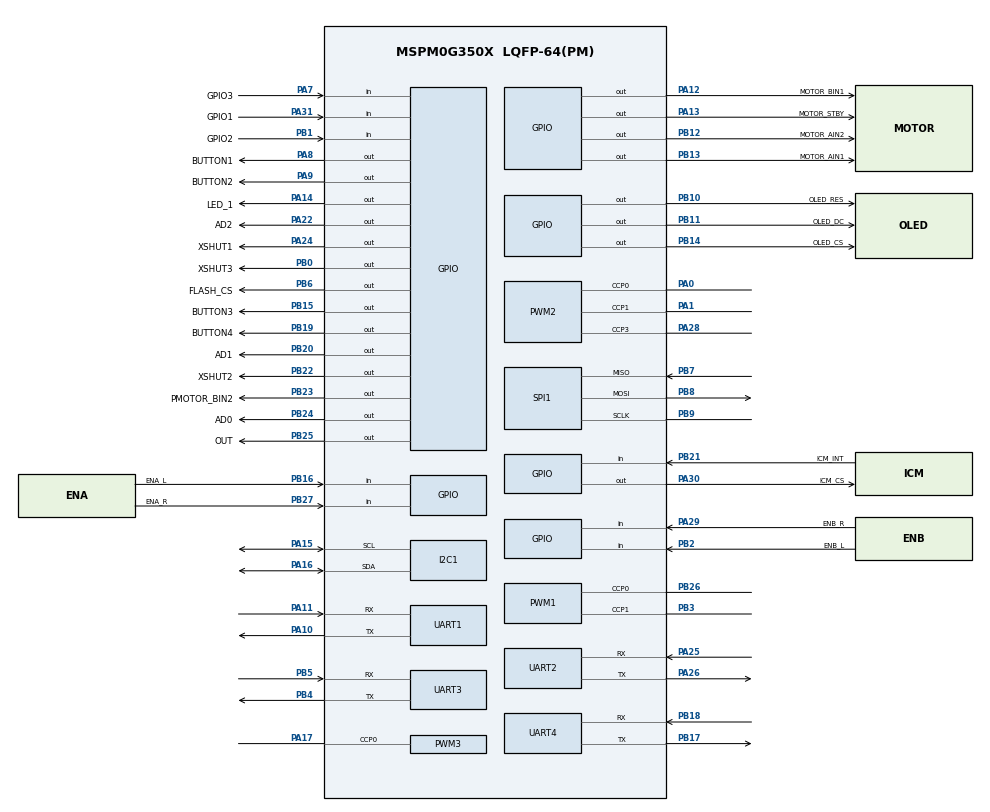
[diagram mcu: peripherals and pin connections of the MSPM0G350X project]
/**
 * @cliArgs --device "MSPM0G350X" --part "Default" --package "LQFP-64(PM)" --product "mspm0_sdk@2.10.00.04"
 * @versions {"tool":"1.26.2+4477"}
 */

/**
 * Import the modules used in this configuration.
 */
const ADC12   = scripting.addModule("/ti/driverlib/ADC12", {}, false);
const ADC121  = ADC12.addInstance();
const GPIO    = scripting.addModule("/ti/driverlib/GPIO", {}, false);
const GPIO1   = GPIO.addInstance();
const GPIO2   = GPIO.addInstance();
const GPIO3   = GPIO.addInstance();
const GPIO4   = GPIO.addInstance();
const GPIO5   = GPIO.addInstance();
const GPIO6   = GPIO.addInstance();
const GPIO7   = GPIO.addInstance();
const GPIO8   = GPIO.addInstance();
const GPIO9   = GPIO.addInstance();
const I2C     = scripting.addModule("/ti/driverlib/I2C", {}, false);
const I2C1    = I2C.addInstance();
const PWM     = scripting.addModule("/ti/driverlib/PWM", {}, false);
const PWM1    = PWM.addInstance();
const PWM2    = PWM.addInstance();
const PWM3    = PWM.addInstance();
const SPI     = scripting.addModule("/ti/driverlib/SPI", {}, false);
const SPI1    = SPI.addInstance();
const SYSCTL  = scripting.addModule("/ti/driverlib/SYSCTL");
const SYSTICK = scripting.addModule("/ti/driverlib/SYSTICK");
const TIMER   = scripting.addModule("/ti/driverlib/TIMER", {}, false);
const TIMER1  = TIMER.addInstance();
const TIMER2  = TIMER.addInstance();
const UART    = scripting.addModule("/ti/driverlib/UART", {}, false);
const UART1   = UART.addInstance();
const UART2   = UART.addInstance();
const UART3   = UART.addInstance();
const UART4   = UART.addInstance();

/**
 * Write custom configuration values to the imported modules.
 */
const divider6       = system.clockTree["PLL_CLK2X_DIV"];
divider6.divideValue = 4;

const divider9       = system.clockTree["UDIV"];
divider9.divideValue = 2;

const multiplier2         = system.clockTree["PLL_QDIV"];
multiplier2.multiplyValue = 5;

const mux4       = system.clockTree["EXHFMUX"];
mux4.inputSelect = "EXHFMUX_XTAL";

const mux8       = system.clockTree["HSCLKMUX"];
mux8.inputSelect = "HSCLKMUX_SYSPLL2X";

ADC121.$name                             = "BAT_ADC";
ADC121.sampClkSrc                        = "DL_ADC12_CLOCK_ULPCLK";
ADC121.sampleTime0                       = "200us";
ADC121.enabledInterrupts                 = ["DL_ADC12_INTERRUPT_MEM0_RESULT_LOADED"];
ADC121.powerDownMode                     = "DL_ADC12_POWER_DOWN_MODE_MANUAL";
ADC121.adcMem0avgen                      = true;
ADC121.hwNumerator                       = "DL_ADC12_HW_AVG_NUM_ACC_8";
ADC121.peripheral.$assign                = "ADC0";
ADC121.peripheral.adcPin0.$assign        = "PA27";
ADC121.adcPin0Config.hideOutputInversion = scripting.forceWrite(false);
ADC121.adcPin0Config.$name               = "ti_driverlib_gpio_GPIOPinGeneric8";

const Board = scripting.addModule("/ti/driverlib/Board", {}, false);

GPIO1.$name                          = "OLED";
GPIO1.associatedPins.create(3);
GPIO1.associatedPins[0].$name        = "OLED_CS";
GPIO1.associatedPins[0].assignedPort = "PORTB";
GPIO1.associatedPins[0].assignedPin  = "14";
GPIO1.associatedPins[0].initialValue = "SET";
GPIO1.associatedPins[0].pin.$assign  = "PB14";
GPIO1.associatedPins[1].$name        = "OLED_DC";
GPIO1.associatedPins[1].assignedPort = "PORTB";
GPIO1.associatedPins[1].assignedPin  = "11";
GPIO1.associatedPins[1].pin.$assign  = "PB11";
GPIO1.associatedPins[2].$name        = "OLED_RES";
GPIO1.associatedPins[2].assignedPort = "PORTB";
GPIO1.associatedPins[2].assignedPin  = "10";
GPIO1.associatedPins[2].pin.$assign  = "PB10";

GPIO2.$name                          = "FLASH";
GPIO2.associatedPins[0].$name        = "FLASH_CS";
GPIO2.associatedPins[0].assignedPort = "PORTB";
GPIO2.associatedPins[0].assignedPin  = "6";
GPIO2.associatedPins[0].initialValue = "SET";
GPIO2.associatedPins[0].pin.$assign  = "PB6";

GPIO3.$name                              = "ICM";
GPIO3.associatedPins.create(2);
GPIO3.associatedPins[0].$name            = "ICM_CS";
GPIO3.associatedPins[0].initialValue     = "SET";
GPIO3.associatedPins[0].internalResistor = "PULL_UP";
GPIO3.associatedPins[0].assignedPort     = "PORTA";
GPIO3.associatedPins[0].assignedPin      = "30";
GPIO3.associatedPins[0].pin.$assign      = "PA30";
GPIO3.associatedPins[1].$name            = "ICM_INT";
GPIO3.associatedPins[1].assignedPort     = "PORTB";
GPIO3.associatedPins[1].assignedPin      = "21";
GPIO3.associatedPins[1].direction        = "INPUT";
GPIO3.associatedPins[1].internalResistor = "PULL_UP";
GPIO3.associatedPins[1].pin.$assign      = "PB21";

GPIO4.$name                          = "MOTOR";
GPIO4.associatedPins.create(5);
GPIO4.associatedPins[0].$name        = "MOTOR_AIN2";
GPIO4.associatedPins[0].assignedPort = "PORTB";
GPIO4.associatedPins[0].assignedPin  = "12";
GPIO4.associatedPins[0].initialValue = "SET";
GPIO4.associatedPins[0].pin.$assign  = "PB12";
GPIO4.associatedPins[1].$name        = "MOTOR_AIN1";
GPIO4.associatedPins[1].assignedPort = "PORTB";
GPIO4.associatedPins[1].assignedPin  = "13";
GPIO4.associatedPins[1].initialValue = "SET";
GPIO4.associatedPins[1].pin.$assign  = "PB13";
GPIO4.associatedPins[2].$name        = "MOTOR_STBY";
GPIO4.associatedPins[2].assignedPort = "PORTA";
GPIO4.associatedPins[2].assignedPin  = "13";
GPIO4.associatedPins[2].pin.$assign  = "PA13";
GPIO4.associatedPins[3].$name        = "MOTOR_BIN1";
GPIO4.associatedPins[3].assignedPort = "PORTA";
GPIO4.associatedPins[3].assignedPin  = "12";
GPIO4.associatedPins[3].initialValue = "SET";
GPIO4.associatedPins[3].pin.$assign  = "PA12";
GPIO4.associatedPins[4].$name        = "PMOTOR_BIN2";
GPIO4.associatedPins[4].assignedPort = "PORTB";
GPIO4.associatedPins[4].assignedPin  = "23";
GPIO4.associatedPins[4].initialValue = "SET";
GPIO4.associatedPins[4].pin.$assign  = "PB23";

GPIO5.$name                               = "ENCODER";
GPIO5.associatedPins.create(4);
GPIO5.associatedPins[0].$name             = "ENA_L";
GPIO5.associatedPins[0].assignedPort      = "PORTB";
GPIO5.associatedPins[0].assignedPin       = "16";
GPIO5.associatedPins[0].direction         = "INPUT";
GPIO5.associatedPins[0].interruptEn       = true;
GPIO5.associatedPins[0].polarity          = "RISE_FALL";
GPIO5.associatedPins[0].interruptPriority = "1";
GPIO5.associatedPins[0].inputFilter       = "8_CYCLES";
GPIO5.associatedPins[0].internalResistor  = "PULL_UP";
GPIO5.associatedPins[0].pin.$assign       = "PB16";
GPIO5.associatedPins[1].$name             = "ENB_L";
GPIO5.associatedPins[1].assignedPort      = "PORTB";
GPIO5.associatedPins[1].assignedPin       = "2";
GPIO5.associatedPins[1].direction         = "INPUT";
GPIO5.associatedPins[1].interruptEn       = true;
GPIO5.associatedPins[1].polarity          = "RISE_FALL";
GPIO5.associatedPins[1].interruptPriority = "1";
GPIO5.associatedPins[1].inputFilter       = "8_CYCLES";
GPIO5.associatedPins[1].internalResistor  = "PULL_UP";
GPIO5.associatedPins[1].pin.$assign       = "PB2";
GPIO5.associatedPins[2].$name             = "ENA_R";
GPIO5.associatedPins[2].assignedPin       = "27";
GPIO5.associatedPins[2].assignedPort      = "PORTB";
GPIO5.associatedPins[2].direction         = "INPUT";
GPIO5.associatedPins[2].interruptEn       = true;
GPIO5.associatedPins[2].polarity          = "RISE_FALL";
GPIO5.associatedPins[2].interruptPriority = "1";
GPIO5.associatedPins[2].inputFilter       = "8_CYCLES";
GPIO5.associatedPins[2].internalResistor  = "PULL_UP";
GPIO5.associatedPins[2].pin.$assign       = "PB27";
GPIO5.associatedPins[3].$name             = "ENB_R";
GPIO5.associatedPins[3].assignedPort      = "PORTA";
GPIO5.associatedPins[3].assignedPin       = "29";
GPIO5.associatedPins[3].direction         = "INPUT";
GPIO5.associatedPins[3].polarity          = "RISE_FALL";
GPIO5.associatedPins[3].interruptEn       = true;
GPIO5.associatedPins[3].interruptPriority = "1";
GPIO5.associatedPins[3].inputFilter       = "8_CYCLES";
GPIO5.associatedPins[3].internalResistor  = "PULL_UP";
GPIO5.associatedPins[3].pin.$assign       = "PA29";

GPIO6.$name                          = "GRAYSCALE";
GPIO6.associatedPins.create(4);
GPIO6.associatedPins[0].$name        = "OUT";
GPIO6.associatedPins[0].assignedPort = "PORTB";
GPIO6.associatedPins[0].assignedPin  = "25";
GPIO6.associatedPins[0].pin.$assign  = "PB25";
GPIO6.associatedPins[1].$name        = "AD0";
GPIO6.associatedPins[1].assignedPort = "PORTB";
GPIO6.associatedPins[1].assignedPin  = "24";
GPIO6.associatedPins[1].pin.$assign  = "PB24";
GPIO6.associatedPins[2].$name        = "AD1";
GPIO6.associatedPins[2].assignedPort = "PORTB";
GPIO6.associatedPins[2].assignedPin  = "20";
GPIO6.associatedPins[2].pin.$assign  = "PB20";
GPIO6.associatedPins[3].$name        = "AD2";
GPIO6.associatedPins[3].assignedPort = "PORTA";
GPIO6.associatedPins[3].assignedPin  = "22";
GPIO6.associatedPins[3].pin.$assign  = "PA22";

GPIO7.$name                               = "LASER";
GPIO7.associatedPins.create(6);
GPIO7.associatedPins[0].$name             = "XSHUT1";
GPIO7.associatedPins[0].assignedPort      = "PORTA";
GPIO7.associatedPins[0].assignedPin       = "24";
GPIO7.associatedPins[0].initialValue      = "SET";
GPIO7.associatedPins[0].pin.$assign       = "PA24";
GPIO7.associatedPins[1].$name             = "GPIO1";
GPIO7.associatedPins[1].assignedPort      = "PORTA";
GPIO7.associatedPins[1].assignedPin       = "31";
GPIO7.associatedPins[1].direction         = "INPUT";
GPIO7.associatedPins[1].interruptEn       = true;
GPIO7.associatedPins[1].polarity          = "FALL";
GPIO7.associatedPins[1].interruptPriority = "3";
GPIO7.associatedPins[1].internalResistor  = "PULL_UP";
GPIO7.associatedPins[1].pin.$assign       = "PA31";
GPIO7.associatedPins[2].$name             = "XSHUT2";
GPIO7.associatedPins[2].assignedPort      = "PORTB";
GPIO7.associatedPins[2].assignedPin       = "22";
GPIO7.associatedPins[2].initialValue      = "SET";
GPIO7.associatedPins[2].pin.$assign       = "PB22";
GPIO7.associatedPins[3].$name             = "GPIO2";
GPIO7.associatedPins[3].assignedPort      = "PORTB";
GPIO7.associatedPins[3].assignedPin       = "1";
GPIO7.associatedPins[3].direction         = "INPUT";
GPIO7.associatedPins[3].polarity          = "FALL";
GPIO7.associatedPins[3].interruptEn       = true;
GPIO7.associatedPins[3].interruptPriority = "3";
GPIO7.associatedPins[3].internalResistor  = "PULL_UP";
GPIO7.associatedPins[3].pin.$assign       = "PB1";
GPIO7.associatedPins[4].$name             = "XSHUT3";
GPIO7.associatedPins[4].assignedPort      = "PORTB";
GPIO7.associatedPins[4].assignedPin       = "0";
GPIO7.associatedPins[4].initialValue      = "SET";
GPIO7.associatedPins[4].pin.$assign       = "PB0";
GPIO7.associatedPins[5].$name             = "GPIO3";
GPIO7.associatedPins[5].assignedPort      = "PORTA";
GPIO7.associatedPins[5].assignedPin       = "7";
GPIO7.associatedPins[5].direction         = "INPUT";
GPIO7.associatedPins[5].interruptEn       = true;
GPIO7.associatedPins[5].polarity          = "FALL";
GPIO7.associatedPins[5].interruptPriority = "3";
GPIO7.associatedPins[5].internalResistor  = "PULL_UP";
GPIO7.associatedPins[5].pin.$assign       = "PA7";

GPIO8.$name                          = "BUTTON";
GPIO8.associatedPins.create(4);
GPIO8.associatedPins[0].$name        = "BUTTON1";
GPIO8.associatedPins[0].assignedPort = "PORTA";
GPIO8.associatedPins[0].assignedPin  = "8";
GPIO8.associatedPins[0].pin.$assign  = "PA8";
GPIO8.associatedPins[1].$name        = "BUTTON2";
GPIO8.associatedPins[1].assignedPort = "PORTA";
GPIO8.associatedPins[1].assignedPin  = "9";
GPIO8.associatedPins[1].pin.$assign  = "PA9";
GPIO8.associatedPins[2].$name        = "BUTTON3";
GPIO8.associatedPins[2].assignedPort = "PORTB";
GPIO8.associatedPins[2].assignedPin  = "15";
GPIO8.associatedPins[2].pin.$assign  = "PB15";
GPIO8.associatedPins[3].$name        = "BUTTON4";
GPIO8.associatedPins[3].assignedPort = "PORTB";
GPIO8.associatedPins[3].assignedPin  = "19";
GPIO8.associatedPins[3].pin.$assign  = "PB19";

GPIO9.$name                          = "LED";
GPIO9.associatedPins[0].$name        = "LED_1";
GPIO9.associatedPins[0].assignedPort = "PORTA";
GPIO9.associatedPins[0].assignedPin  = "14";
GPIO9.associatedPins[0].initialValue = "SET";
GPIO9.associatedPins[0].pin.$assign  = "PA14";

I2C1.$name                           = "I2C_0";
I2C1.basicEnableController           = true;
I2C1.basicControllerStandardBusSpeed = "FastPlus";
I2C1.peripheral.$assign              = "I2C1";
I2C1.peripheral.sdaPin.$assign       = "PA16";
I2C1.peripheral.sclPin.$assign       = "PA15";
I2C1.sdaPinConfig.$name              = "ti_driverlib_gpio_GPIOPinGeneric9";
I2C1.sclPinConfig.$name              = "ti_driverlib_gpio_GPIOPinGeneric15";

PWM1.$name                              = "PWM_Motor";
PWM1.pwmMode                            = "EDGE_ALIGN_UP";
PWM1.timerStartTimer                    = true;
PWM1.clockDivider                       = 4;
PWM1.peripheral.$assign                 = "TIMG6";
PWM1.peripheral.ccp0Pin.$assign         = "PB26";
PWM1.peripheral.ccp1Pin.$assign         = "PB3";
PWM1.PWM_CHANNEL_0.$name                = "ti_driverlib_pwm_PWMTimerCC0";
PWM1.PWM_CHANNEL_1.$name                = "ti_driverlib_pwm_PWMTimerCC2";
PWM1.ccp0PinConfig.direction            = scripting.forceWrite("OUTPUT");
PWM1.ccp0PinConfig.hideOutputInversion  = scripting.forceWrite(false);
PWM1.ccp0PinConfig.onlyInternalResistor = scripting.forceWrite(false);
PWM1.ccp0PinConfig.passedPeripheralType = scripting.forceWrite("Digital");
PWM1.ccp0PinConfig.$name                = "ti_driverlib_gpio_GPIOPinGeneric11";
PWM1.ccp1PinConfig.direction            = scripting.forceWrite("OUTPUT");
PWM1.ccp1PinConfig.hideOutputInversion  = scripting.forceWrite(false);
PWM1.ccp1PinConfig.onlyInternalResistor = scripting.forceWrite(false);
PWM1.ccp1PinConfig.passedPeripheralType = scripting.forceWrite("Digital");
PWM1.ccp1PinConfig.$name                = "ti_driverlib_gpio_GPIOPinGeneric10";

PWM2.$name                              = "PWM_SERVO";
PWM2.ccIndex                            = [0,1,3];
PWM2.PWM_CHANNEL_0.$name                = "ti_driverlib_pwm_PWMTimerCC1";
PWM2.PWM_CHANNEL_1.$name                = "ti_driverlib_pwm_PWMTimerCC3";
PWM2.ccp0PinConfig.direction            = scripting.forceWrite("OUTPUT");
PWM2.ccp0PinConfig.hideOutputInversion  = scripting.forceWrite(false);
PWM2.ccp0PinConfig.onlyInternalResistor = scripting.forceWrite(false);
PWM2.ccp0PinConfig.passedPeripheralType = scripting.forceWrite("Digital");
PWM2.ccp0PinConfig.$name                = "ti_driverlib_gpio_GPIOPinGeneric12";
PWM2.ccp1PinConfig.direction            = scripting.forceWrite("OUTPUT");
PWM2.ccp1PinConfig.hideOutputInversion  = scripting.forceWrite(false);
PWM2.ccp1PinConfig.onlyInternalResistor = scripting.forceWrite(false);
PWM2.ccp1PinConfig.passedPeripheralType = scripting.forceWrite("Digital");
PWM2.ccp1PinConfig.$name                = "ti_driverlib_gpio_GPIOPinGeneric13";
PWM2.peripheral.$assign                 = "TIMA0";
PWM2.peripheral.ccp0Pin.$assign         = "PA0";
PWM2.peripheral.ccp1Pin.$assign         = "PA1";
PWM2.peripheral.ccp3Pin.$assign         = "PA28";
PWM2.PWM_CHANNEL_3.$name                = "ti_driverlib_pwm_PWMTimerCC4";
PWM2.ccp3PinConfig.$name                = "ti_driverlib_gpio_GPIOPinGeneric14";

PWM3.$name                              = "PWM_BUZZER";
PWM3.ccIndex                            = [0];
PWM3.PWM_CHANNEL_0.$name                = "ti_driverlib_pwm_PWMTimerCC5";
PWM3.ccp0PinConfig.direction            = scripting.forceWrite("OUTPUT");
PWM3.ccp0PinConfig.hideOutputInversion  = scripting.forceWrite(false);
PWM3.ccp0PinConfig.onlyInternalResistor = scripting.forceWrite(false);
PWM3.ccp0PinConfig.passedPeripheralType = scripting.forceWrite("Digital");
PWM3.ccp0PinConfig.$name                = "ti_driverlib_gpio_GPIOPinGeneric5";
PWM3.peripheral.$assign                 = "TIMA1";
PWM3.peripheral.ccp0Pin.$assign         = "PA17";

SPI1.frameFormat                        = "MOTO3";
SPI1.$name                              = "SPI_1";
SPI1.targetBitRate                      = 20000000;
SPI1.sclkPinConfig.direction            = scripting.forceWrite("OUTPUT");
SPI1.sclkPinConfig.onlyInternalResistor = scripting.forceWrite(false);
SPI1.sclkPinConfig.passedPeripheralType = scripting.forceWrite("Digital");
SPI1.sclkPinConfig.$name                = "ti_driverlib_gpio_GPIOPinGeneric0";
SPI1.mosiPinConfig.direction            = scripting.forceWrite("OUTPUT");
SPI1.mosiPinConfig.hideOutputInversion  = scripting.forceWrite(false);
SPI1.mosiPinConfig.onlyInternalResistor = scripting.forceWrite(false);
SPI1.mosiPinConfig.passedPeripheralType = scripting.forceWrite("Digital");
SPI1.mosiPinConfig.$name                = "ti_driverlib_gpio_GPIOPinGeneric1";
SPI1.misoPinConfig.onlyInternalResistor = scripting.forceWrite(false);
SPI1.misoPinConfig.passedPeripheralType = scripting.forceWrite("Digital");
SPI1.misoPinConfig.$name                = "ti_driverlib_gpio_GPIOPinGeneric2";
SPI1.misoPinConfig.enableConfig         = true;
SPI1.peripheral.$assign                 = "SPI1";
SPI1.peripheral.sclkPin.$assign         = "PB9";
SPI1.peripheral.mosiPin.$assign         = "PB8";
SPI1.peripheral.misoPin.$assign         = "PB7";

SYSCTL.forceDefaultClkConfig = true;
SYSCTL.clockTreeEn           = true;

SYSTICK.periodEnable      = true;
SYSTICK.interruptEnable   = true;
SYSTICK.interruptPriority = "0";
SYSTICK.systickEnable     = true;
SYSTICK.period            = 80000;

TIMER1.interrupts  = ["ZERO"];
TIMER1.$name       = "TIMER_10ms";
TIMER1.timerPeriod = "10ms";
TIMER1.timerClkDiv = 8;
TIMER1.timerMode   = "PERIODIC";

TIMER2.$name              = "TIMER_2ms";
TIMER2.timerMode          = "PERIODIC";
TIMER2.interrupts         = ["ZERO"];
TIMER2.timerClkDiv        = 4;
TIMER2.interruptPriority  = "1";
TIMER2.timerPeriod        = "2ms";
TIMER2.peripheral.$assign = "TIMG7";

UART1.$name                            = "UART";
UART1.targetBaudRate                   = 115200;
UART1.enabledInterrupts                = ["RX"];
UART1.peripheral.$assign               = "UART0";
UART1.peripheral.rxPin.$assign         = "PA11";
UART1.peripheral.txPin.$assign         = "PA10";
UART1.txPinConfig.direction            = scripting.forceWrite("OUTPUT");
UART1.txPinConfig.hideOutputInversion  = scripting.forceWrite(false);
UART1.txPinConfig.onlyInternalResistor = scripting.forceWrite(false);
UART1.txPinConfig.passedPeripheralType = scripting.forceWrite("Digital");
UART1.txPinConfig.$name                = "ti_driverlib_gpio_GPIOPinGeneric6";
UART1.rxPinConfig.hideOutputInversion  = scripting.forceWrite(false);
UART1.rxPinConfig.onlyInternalResistor = scripting.forceWrite(false);
UART1.rxPinConfig.passedPeripheralType = scripting.forceWrite("Digital");
UART1.rxPinConfig.$name                = "ti_driverlib_gpio_GPIOPinGeneric7";
UART1.rxPinConfig.enableConfig         = true;
UART1.rxPinConfig.internalResistor     = "PULL_UP";

UART2.$name                            = "UART_3";
UART2.peripheral.$assign               = "UART3";
UART2.peripheral.rxPin.$assign         = "PA25";
UART2.peripheral.txPin.$assign         = "PA26";
UART2.txPinConfig.direction            = scripting.forceWrite("OUTPUT");
UART2.txPinConfig.hideOutputInversion  = scripting.forceWrite(false);
UART2.txPinConfig.onlyInternalResistor = scripting.forceWrite(false);
UART2.txPinConfig.passedPeripheralType = scripting.forceWrite("Digital");
UART2.txPinConfig.$name                = "ti_driverlib_gpio_GPIOPinGeneric16";
UART2.rxPinConfig.hideOutputInversion  = scripting.forceWrite(false);
UART2.rxPinConfig.onlyInternalResistor = scripting.forceWrite(false);
UART2.rxPinConfig.passedPeripheralType = scripting.forceWrite("Digital");
UART2.rxPinConfig.$name                = "ti_driverlib_gpio_GPIOPinGeneric17";

UART3.$name                            = "UART_WIRELESS";
UART3.peripheral.$assign               = "UART1";
UART3.peripheral.rxPin.$assign         = "PB5";
UART3.peripheral.txPin.$assign         = "PB4";
UART3.txPinConfig.direction            = scripting.forceWrite("OUTPUT");
UART3.txPinConfig.hideOutputInversion  = scripting.forceWrite(false);
UART3.txPinConfig.onlyInternalResistor = scripting.forceWrite(false);
UART3.txPinConfig.passedPeripheralType = scripting.forceWrite("Digital");
UART3.txPinConfig.$name                = "ti_driverlib_gpio_GPIOPinGeneric18";
UART3.rxPinConfig.hideOutputInversion  = scripting.forceWrite(false);
UART3.rxPinConfig.onlyInternalResistor = scripting.forceWrite(false);
UART3.rxPinConfig.passedPeripheralType = scripting.forceWrite("Digital");
UART3.rxPinConfig.$name                = "ti_driverlib_gpio_GPIOPinGeneric19";

UART4.$name                            = "UART_CAMERA";
UART4.peripheral.$assign               = "UART2";
UART4.peripheral.rxPin.$assign         = "PB18";
UART4.peripheral.txPin.$assign         = "PB17";
UART4.txPinConfig.direction            = scripting.forceWrite("OUTPUT");
UART4.txPinConfig.hideOutputInversion  = scripting.forceWrite(false);
UART4.txPinConfig.onlyInternalResistor = scripting.forceWrite(false);
UART4.txPinConfig.passedPeripheralType = scripting.forceWrite("Digital");
UART4.txPinConfig.$name                = "ti_driverlib_gpio_GPIOPinGeneric3";
UART4.rxPinConfig.hideOutputInversion  = scripting.forceWrite(false);
UART4.rxPinConfig.onlyInternalResistor = scripting.forceWrite(false);
UART4.rxPinConfig.passedPeripheralType = scripting.forceWrite("Digital");
UART4.rxPinConfig.$name                = "ti_driverlib_gpio_GPIOPinGeneric4";

/**
 * Pinmux solution for unlocked pins/peripherals. This ensures that minor changes to the automatic solver in a future
 * version of the tool will not impact the pinmux you originally saw.  These lines can be completely deleted in order to
 * re-solve from scratch.
 */
Board.peripheral.$suggestSolution          = "DEBUGSS";
Board.peripheral.swclkPin.$suggestSolution = "PA20";
Board.peripheral.swdioPin.$suggestSolution = "PA19";
TIMER1.peripheral.$suggestSolution         = "TIMG0";
